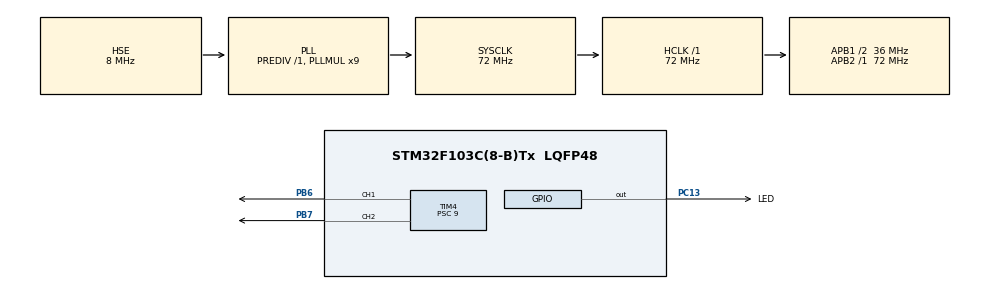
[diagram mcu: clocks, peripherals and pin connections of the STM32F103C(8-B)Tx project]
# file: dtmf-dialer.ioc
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Mcu.Family=STM32F1
RCC.PLLSourceVirtual=RCC_PLLSOURCE_HSE
TIM4.Channel-PWM\ Generation1\ CH1=TIM_CHANNEL_1
TIM4.AutoReloadPreload=TIM_AUTORELOAD_PRELOAD_ENABLE
PD1-OSC_OUT.Mode=HSE-External-Oscillator
PC13-TAMPER-RTC.Signal=GPIO_Output
PD0-OSC_IN.Signal=RCC_OSC_IN
RCC.APB1CLKDivider=RCC_HCLK_DIV2
RCC.SYSCLKSource=RCC_SYSCLKSOURCE_PLLCLK
ProjectManager.StackSize=0x400
PD1-OSC_OUT.Signal=RCC_OSC_OUT
PA13.Signal=SYS_JTMS-SWDIO
ProjectManager.TargetToolchain=Other Toolchains (GPDSC)
TIM4.OCFastMode_PWM-PWM\ Generation1\ CH1=TIM_OCFAST_ENABLE
RCC.HCLKFreq_Value=72000000
RCC.APB2TimFreq_Value=72000000
TIM4.Pulse-PWM\ Generation1\ CH1=128
PB6.Signal=S_TIM4_CH1
RCC.USBFreq_Value=72000000
TIM4.Prescaler=9
RCC.AHBFreq_Value=72000000
PD0-OSC_IN.Mode=HSE-External-Oscillator
PB3.Mode=JTAG_4_pins
board=custom
PA15.Mode=JTAG_4_pins
PC13-TAMPER-RTC.GPIO_Label=LED
RCC.PLLMUL=RCC_PLL_MUL9
TIM4.Channel-PWM\ Generation2\ CH2=TIM_CHANNEL_2
RCC.APB2Freq_Value=72000000
PC13-TAMPER-RTC.PinState=GPIO_PIN_RESET
PA14.Mode=JTAG_4_pins
SH.S_TIM4_CH2.0=TIM4_CH2,PWM Generation2 CH2
PB7.Signal=S_TIM4_CH2
TIM4.Period=255
PC13-TAMPER-RTC.GPIO_Speed=GPIO_SPEED_FREQ_HIGH
PA13.Mode=JTAG_4_pins
Mcu.Name=STM32F103C(8-B)Tx
PB3.Signal=SYS_JTDO-TRACESWO
RCC.SYSCLKFreq_VALUE=72000000
Mcu.Package=LQFP48
PC13-TAMPER-RTC.GPIO_ModeDefaultOutputPP=GPIO_MODE_OUTPUT_PP
PA14.Signal=SYS_JTCK-SWCLK
PA15.Signal=SYS_JTDI
ProjectManager.HeapSize=0x200
NVIC.PriorityGroup=NVIC_PRIORITYGROUP_4
SH.S_TIM4_CH1.0=TIM4_CH1,PWM Generation1 CH1
RCC.APB1TimFreq_Value=72000000
NVIC.TIM4_IRQn=true\:0\:0\:false\:false\:true\:true\:true
RCC.APB1Freq_Value=36000000

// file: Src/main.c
/* USER CODE BEGIN Header */
/**
  ******************************************************************************
  * @file           : main.c
  * @brief          : Main program body
  ******************************************************************************
  * @attention
  *
  * <h2><center>&copy; Copyright (c) 2020 STMicroelectronics.
  * All rights reserved.</center></h2>
  *
  * This software component is licensed by ST under BSD 3-Clause license,
  * the "License"; You may not use this file except in compliance with the
  * License. You may obtain a copy of the License at:
  *                        opensource.org/licenses/BSD-3-Clause
  *
  ******************************************************************************
  */
/* USER CODE END Header */
#include "main.h"
#include "tim.h"
#include "gpio.h"

void SystemClock_Config(void);

/* USER CODE BEGIN 0 */

void keypad_on_press(const char ch) {
  tone_stop();
  tone_play(ch);
}

void keypad_on_release(void) {
  tone_stop();
}

/* USER CODE END 0 */

int main(void)
{

  /* MCU Configuration--------------------------------------------------------*/

  /* Reset of all peripherals, Initializes the Flash interface and the Systick. */
  HAL_Init();

  /* Configure the system clock */
  SystemClock_Config();

  /* Initialize all configured peripherals */
  MX_GPIO_Init();
  MX_TIM4_Init();
  /* USER CODE BEGIN 2 */
  HAL_TIM_PWM_Start_IT(&htim4, TIM_CHANNEL_1);
  tone_init();
  tone_play('1');

  /* USER CODE END 2 */

  /* Infinite loop */
  /* USER CODE BEGIN WHILE */
  while (1)
  {
    // show what code is operational
    HAL_GPIO_TogglePin(LED_GPIO_Port, LED_Pin);
    HAL_Delay(1000);
    /* USER CODE END WHILE */

  }
}

void SystemClock_Config(void)
{
  RCC_OscInitTypeDef RCC_OscInitStruct = {0};
  RCC_ClkInitTypeDef RCC_ClkInitStruct = {0};

  /** Initializes the RCC Oscillators according to the specified parameters
  * in the RCC_OscInitTypeDef structure.
  */
  RCC_OscInitStruct.OscillatorType = RCC_OSCILLATORTYPE_HSE;
  RCC_OscInitStruct.HSEState = RCC_HSE_ON;
  RCC_OscInitStruct.HSEPredivValue = RCC_HSE_PREDIV_DIV1;
  RCC_OscInitStruct.HSIState = RCC_HSI_ON;
  RCC_OscInitStruct.PLL.PLLState = RCC_PLL_ON;
  RCC_OscInitStruct.PLL.PLLSource = RCC_PLLSOURCE_HSE;
  RCC_OscInitStruct.PLL.PLLMUL = RCC_PLL_MUL9;
  if (HAL_RCC_OscConfig(&RCC_OscInitStruct) != HAL_OK)
  {
    Error_Handler();
  }
  /** Initializes the CPU, AHB and APB buses clocks
  */
  RCC_ClkInitStruct.ClockType = RCC_CLOCKTYPE_HCLK|RCC_CLOCKTYPE_SYSCLK
                              |RCC_CLOCKTYPE_PCLK1|RCC_CLOCKTYPE_PCLK2;
  RCC_ClkInitStruct.SYSCLKSource = RCC_SYSCLKSOURCE_PLLCLK;
  RCC_ClkInitStruct.AHBCLKDivider = RCC_SYSCLK_DIV1;
  RCC_ClkInitStruct.APB1CLKDivider = RCC_HCLK_DIV2;
  RCC_ClkInitStruct.APB2CLKDivider = RCC_HCLK_DIV1;

  if (HAL_RCC_ClockConfig(&RCC_ClkInitStruct, FLASH_LATENCY_2) != HAL_OK)
  {
    Error_Handler();
  }
}

void Error_Handler(void)
{
  /* USER CODE BEGIN Error_Handler_Debug */
  /* User can add his own implementation to report the HAL error return state */
  HAL_NVIC_SystemReset();
  /* USER CODE END Error_Handler_Debug */
}

/************************ (C) COPYRIGHT STMicroelectronics *****END OF FILE****/
